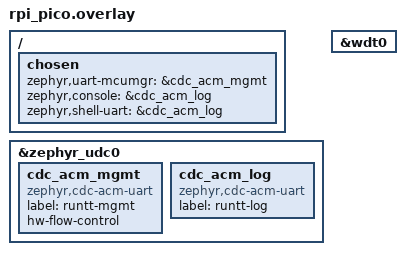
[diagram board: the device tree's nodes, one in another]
/*
 * Dual CDC-ACM composite on RP2040: the two contract channels as USB endpoints
 * rather than the ptys native_sim gives us. Same shape, different transport.
 *
 * The `label` on each instance becomes the USB **interface string descriptor**,
 * which is the part of the contract the firmware owns and the part our udev
 * rules match on. We deliberately do not key off VID/PID: a customer may ship
 * their own VID, and interface numbering is not contractual either (ID_PATH is
 * interface-suffixed, so the two channels of one composite device land on
 * different ID_PATHs).
 */

&zephyr_udc0 {
	cdc_acm_mgmt: cdc_acm_mgmt {
		compatible = "zephyr,cdc-acm-uart";
		label = "runtt-mgmt";
		/*
		 * Not optional for SMP. Without it CDC-ACM silently DROPS
		 * received data when the class has no buffer queued, and
		 * zephyr#107633's conclusion is blunt: "any protocol that
		 * relies on data not being dropped cannot work". Zephyr's own
		 * smp_svr USB overlay carries this property for exactly that
		 * reason.
		 *
		 * On RP2040 the consequence is worse than a dropped packet. A
		 * bulk OUT completing with no buffer queued takes
		 * udc_rpi_pico.c's `buf == NULL` path, which clears the
		 * BUFF_STATUS bit, logs, and returns WITHOUT re-arming -- so
		 * the endpoint is dead for good. Observed on hardware as
		 * EP1 OUT = FULL, LENGTH=7, AVAILABLE=0, with the board
		 * enumerated and answering control transfers while completely
		 * unmanageable.
		 */
		hw-flow-control;
	};

	cdc_acm_log: cdc_acm_log {
		compatible = "zephyr,cdc-acm-uart";
		label = "runtt-log";
		/*
		 * Deliberately NO hw-flow-control here, unlike the management
		 * channel. The property means "block instead of drop": with it
		 * set, poll_out blocks once the TX buffer is full
		 * (usbd_cdc_acm.c:104-107). That is correct for SMP, which
		 * cannot tolerate loss -- and fatal for a console, which no one
		 * may be reading.
		 *
		 * Setting it here bricked boot: the log backend blocks on the
		 * first message before USB has enumerated, so the device never
		 * finishes coming up and never appears on the host at all.
		 * Losing log output under backpressure is the correct
		 * trade for this channel.
		 */
	};
};

/ {
	chosen {
		/* Channel 1: SMP management. */
		zephyr,uart-mcumgr = &cdc_acm_mgmt;

		/* Channel 2: application log output, which the runtime pipes to
		 * container stdio.
		 */
		zephyr,console = &cdc_acm_log;
		zephyr,shell-uart = &cdc_acm_log;
	};
};

/* The SoC's watchdog, for CONFIG_RUNTT_WATCHDOG (Layer 2: a halted CPU still
 * reverts). Enabling the node does not arm anything -- the Kconfig option and
 * src/watchdog.c do that -- so this is safe for firmware that leaves the
 * watchdog off.
 */
&wdt0 {
	status = "okay";
};
